# AT32UC3A3128S device description
Architecture: AVR32_UC3; Family: AVR UC3
Registers are 32-bit, read-write, reset 0x0 unless marked. A register's access mark holds for its fields unless they carry their own. Offsets are from the block's base; [hi:lo] are bit positions; {n}, {i} and the like mark numbered series; 'fields as' and 'values as' point back to an identical list.

## CORE
Instances: CORE 0 in sysreg
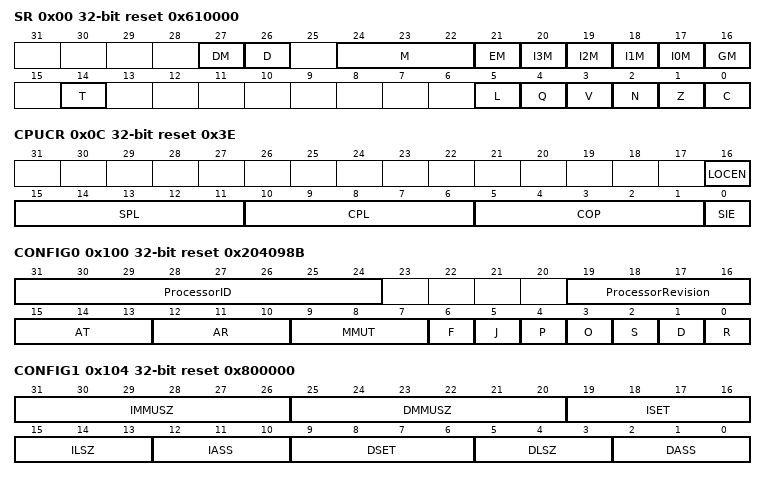
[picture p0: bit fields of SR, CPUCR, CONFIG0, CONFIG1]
0x00 SR reset 0x610000 — Status Register
  [27] DM — Debug State Mask
  [26] D — Debug state
  [24:22] M — Execution Mode bits
    0=APP; 1=SUP; {v}=INT{v-2} (v=2..5); 6=EX; 7=NMI
  [21] EM — Exception Mask
  [n+17] I{n}M (n=0..3) — Interrupt Level {n} Mask
  [16] GM — Global Interrupt Mask
  [14] T — Scratch
  [5] L — Lock
  [4] Q — Saturation
  [3] V — Overflow
  [2] N — Sign
  [1] Z — Zero
  [0] C — Carry
0x04 EVBA — Exception Vector Base Address
0x08 ACBA — Application Call Base Address
0x0C CPUCR reset 0x3E — CPU Control Register
  [16] LOCEN — Local Bus Enable
  [15:11] SPL — Slave Pending Limit
  [10:6] CPL — CPU Pending Limit
  [5:1] COP — CPU Ownership Period
  [0] SIE — Slave Interface Enable
0x10 ECR ro — Exception Cause Register
  [31:0] ECR — Exception cause
    0=UNRECOVERABLE; 1=TLB_MULTIPLE; 2=BUS_ERROR_WRITE; 3=BUS_ERROR_READ; 4=NMI; 5=ADDR_ALIGN_X; 6=PROTECTION_X; 7=DEBUG; 8=ILLEGAL_OPCODE; 9=UNIMPL_INSTRUCTION; 10=PRIVILEGE_VIOLATION; 11=FPE; 12=COPROC_ABSENT; 13=ADDR_ALIGN_R; 14=ADDR_ALIGN_W; 15=PROTECTION_R; 16=PROTECTION_W; 17=DTLB_MODIFIED; 20=TLB_MISS_X; 24=TLB_MISS_R; 28=TLB_MISS_W
0x30 RSR_DBG — Return Status Register for Debug mode
0x50 RAR_DBG — Return Address Register for Debug mode
0x100 CONFIG0 ro reset 0x204098B — Configuration Register 0
  [31:24] ProcessorID
  [19:16] ProcessorRevision — Processor Revison
  [15:13] AT — Architecture Type
  [12:10] AR — Architecture Revision
  [9:7] MMUT — MMU Type
  [6] F — Floating-point unit implemented
  [5] J — Java extension implemented
  [4] P — Performance counters implemented
  [3] O — On-chip debug implemented
  [2] S — SIMD instructions implemented
  [1] D — DSP instructions implemented
  [0] R — Memory Read-Modify-Write instructions implemented
0x104 CONFIG1 ro reset 0x800000 — Configuration register 1
  [31:26] IMMUSZ — IMMU Size
  [25:20] DMMUSZ — DMMU Size
  [19:16] ISET — Number of sets in the ICACHE
  [15:13] ILSZ — Line size in ICACHE
  [12:10] IASS — Associativity of ICACHE
  [9:6] DSET — Number of sets in the DCACHE
  [5:3] DLSZ — Line size in DCACHE
  [2:0] DASS — Associativity of DCACHE
0x108 COUNT — Cycle Counter Register
0x10C COMPARE
0x13C BEAR — Bus Error Address Register
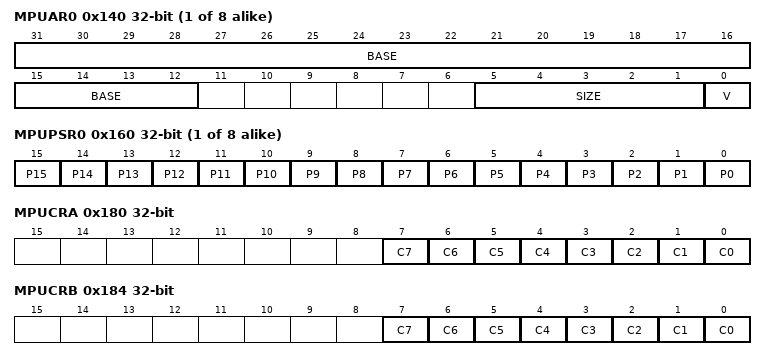
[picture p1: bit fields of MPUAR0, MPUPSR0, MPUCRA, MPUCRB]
{0x140+4i} MPUAR{i} (i=0..7) — MPU Address Register Instruction {i}
  [31:12] BASE — Base address of the region
  [5:1] SIZE — Size of the region
  [0] V — Valid
{0x160+4i} MPUPSR{i} (i=0..7) — MPU Address Register Data {i}
  [n] P{n} (n=0..15)
0x180 MPUCRA — MPU Cacheable Register A
  [n] C{n} (n=0..7)
0x184 MPUCRB — MPU Cacheable Register B
  [n] C{n} (n=0..7)
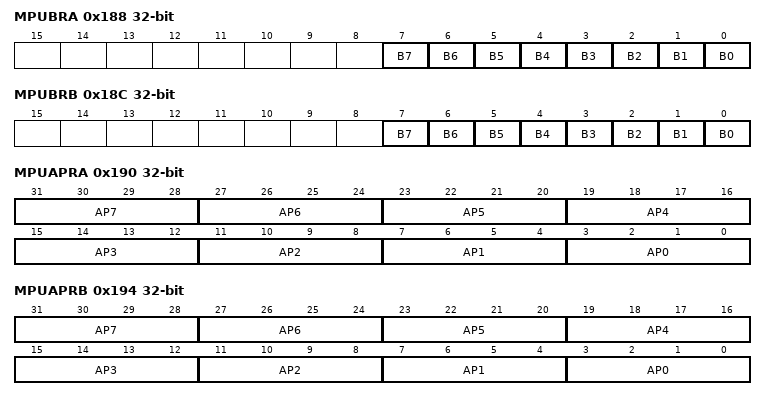
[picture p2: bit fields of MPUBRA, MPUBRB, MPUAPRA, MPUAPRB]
0x188 MPUBRA — MPU Bufferable Register A
  [n] B{n} (n=0..7)
0x18C MPUBRB — MPU Bufferable Register B
  [all] fields
    1=EXECUTE; 2=WRITE; 4=USER; 8=SUP_WRITE
  [n] B{n} (n=0..7)
0x190 MPUAPRA — MPU Access Permission Register A
  [all] fields
    1=EXECUTE; 2=WRITE; 4=USER; 8=SUP_WRITE
  [4n+3:4n] AP{n} (n=0..7) — Access Permissions for MPU region {n}
0x194 MPUAPRB — MPU Access Permission Register B
  fields as MPUAPRA
0x198 MPUCR — MPU Control Register
  [0] E — MPU Enable
0x3E0 MSU_ADDRHI — Memory Service Unit Address High Register
  [3:0] ADDRHI — Address High Part
0x3E4 MSU_ADDRLO — Memory Service Unit Address Low Register
  [31:2] ADDRLO — Address Low Part
0x3E8 MSU_LENGTH — Memory Service Unit Length Register
  [31:2] LENGTH — Length value
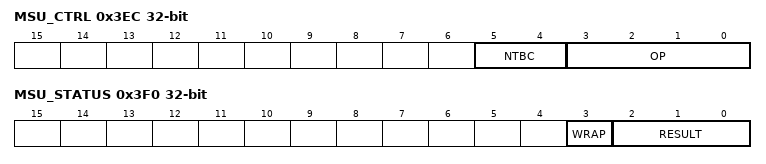
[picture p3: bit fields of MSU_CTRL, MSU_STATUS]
0x3EC MSU_CTRL — Memory Service Unit Control Register
  [5:4] NTBC — NanoTrace Buffer Control
  [3:0] OP — Requested Operation
0x3F0 MSU_STATUS ro — Memory Service Unit Status Register
  [3] WRAP
  [2:0] RESULT — Result of current or last operation
0x3F4 MSU_DATA — Memory Service Unit Data Register
  [31:0] DATA — Generic Data Register
0x3F8 MSU_TAIL — Memory Service Unit Tail Register
  [31:2] TAIL — Tail Address Register for NanoTrace buffer
